# BSC register map
File version: 1
BCM2711 Broadcom Serial Controller, I2C master (BSC0, BSC1, BSC3 to BSC6)
Registers are read-write, no defined reset value unless marked. A register's access mark holds for its fields unless they carry their own. Offsets are from the block's base; lines under a group give offsets from that group; [hi:lo] are bit positions; {n}, {i} and the like mark numbered series; 'fields as' and 'values as' point back to an identical list; <NAME> marks a mode.

## Memory map
0x00000000 BSC size 0x20

## BSC
Base 0x00000000
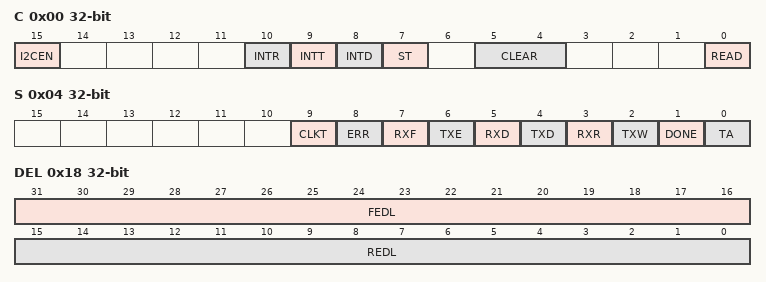
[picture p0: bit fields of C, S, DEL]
0x00 C — Control (Table 25): enables, the transfer's direction, and the one-shot FIFO clear and start, which read back 0
  [15] I2CEN — 1 enables the controller; while 0 no transfer runs, registers stay accessible
  [10] INTR — Interrupt while S.RXR is 1
  [9] INTT — Interrupt while S.TXW is 1
  [8] INTD — Interrupt while S.DONE is 1
  [7] ST — 1 starts a transfer, one-shot, read back 0
  [5:4] CLEAR — Either bit set clears the FIFO, one-shot, read back 0; set with ST, the FIFO is cleared before the transfer starts; clearing during a transfer aborts it
  [0] READ — 0 a write transfer, 1 a read transfer
0x04 S — Status (Table 26): activity, FIFO levels and the transfer's errors; DONE, ERR and CLKT clear by writing 1, writing 0 has no effect
  [9] CLKT write-1-clears — 1 once the slave stretches the clock past CLKT.TOUT; unverified which level: Table 26 says SCL held low, the section's text says high
  [8] ERR write-1-clears — 1 once the slave fails to acknowledge: its address in Table 26, its address or a written data byte in the section's text
  [7] RXF ro — 1 while the FIFO is full; a read stalls until data is removed
  [6] TXE ro — 1 while the FIFO is empty
  [5] RXD ro — 1 while the FIFO holds a byte; a read of an empty FIFO returns invalid data
  [4] TXD ro — 1 while the FIFO has room for a byte; a write to a full FIFO is ignored
  [3] RXR ro — 1 during a read while the FIFO is three quarters full or more; cleared by reading enough data
  [2] TXW ro — 1 during a write while the FIFO is less than a quarter full; cleared by writing enough data
  [1] DONE write-1-clears — 1 once the transfer completes
  [0] TA ro — 1 while a transfer is active
0x08 DLEN — Data length (Table 27): a write sets the transfer's byte count; a read returns the bytes still to move while TA or DONE is 1, and the last value written otherwise
  [15:0] DLEN
0x0C A — Slave address (Table 28), kept across transfers
  [6:0] ADDR
0x10 FIFO read-modifies — Data FIFO (Table 29): a write queues a byte to send, a read takes the next byte received
  [7:0] DATA
0x14 DIV — Clock divider (Table 30): SCL is the core clock divided by CDIV, rounded down to even; 0 divides by 32768
  [15:0] CDIV
0x18 DEL — Data delay (Table 31), in core clocks; each must stay below CDIV / 2
  [31:16] FEDL — Clocks after SCL's falling edge before the next bit is driven
  [15:0] REDL — Clocks after SCL's rising edge before the input is sampled
0x1C CLKT — Clock stretch timeout (Table 32): SCL clocks the master waits on a stretching slave before setting S.CLKT; 0 disables the timeout
  [15:0] TOUT

## Notices in the file
Copyright (c) 2026, Stanislav Sedov <stas@deglitch.com>
SPDX-License-Identifier: BSD-2-Clause
